# iospear600 register map
Registers are 32-bit, access not given, no defined reset value unless marked. A register's access mark holds for its fields unless they carry their own. Addresses are absolute; registers are grouped by the start of their names; [hi:lo] are bit positions; {n}, {i} and the like mark numbered series; 'fields as' and 'values as' point back to an identical list.

## TIMERB
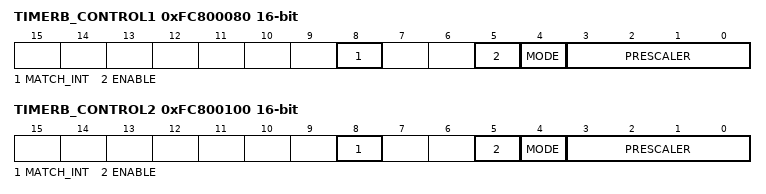
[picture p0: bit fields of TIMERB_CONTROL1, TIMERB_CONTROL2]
0xFC800080 TIMERB_CONTROL1 16-bit
  [8] MATCH_INT, [5] ENABLE, [4] MODE, [3:0] PRESCALER
0xFC800084 TIMERB_STATUS_INT_ACK1 16-bit
  [0] MATCH
0xFC800088 TIMERB_COMPARE1 16-bit
0xFC80008C TIMERB_COUNT1 16-bit
0xFC800090 TIMERB_REDG_CAPT1 16-bit
0xFC800094 TIMERB_FEDG_CAPT1 16-bit
0xFC800100 TIMERB_CONTROL2 16-bit
  [8] MATCH_INT, [5] ENABLE, [4] MODE, [3:0] PRESCALER
0xFC800104 TIMERB_STATUS_INT_ACK2 16-bit
  [0] MATCH
0xFC800108 TIMERB_COMPARE2 16-bit
0xFC80010C TIMERB_COUNT2 16-bit
0xFC800110 TIMERB_REDG_CAPT2 16-bit
0xFC800114 TIMERB_FEDG_CAPT2 16-bit

## TIMER1
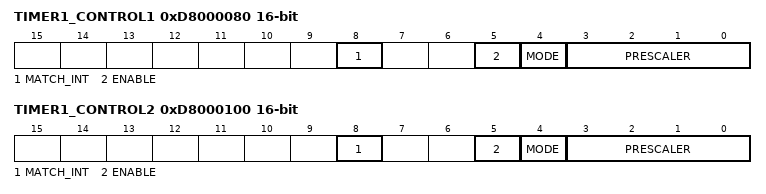
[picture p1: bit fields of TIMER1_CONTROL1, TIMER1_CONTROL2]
0xD8000080 TIMER1_CONTROL1 16-bit
  [8] MATCH_INT, [5] ENABLE, [4] MODE, [3:0] PRESCALER
0xD8000084 TIMER1_STATUS_INT_ACK1 16-bit
  [0] MATCH
0xD8000088 TIMER1_COMPARE1 16-bit
0xD800008C TIMER1_COUNT1 16-bit
0xD8000090 TIMER1_REDG_CAPT1 16-bit
0xD8000094 TIMER1_FEDG_CAPT1 16-bit
0xD8000100 TIMER1_CONTROL2 16-bit
  [8] MATCH_INT, [5] ENABLE, [4] MODE, [3:0] PRESCALER
0xD8000104 TIMER1_STATUS_INT_ACK2 16-bit
  [0] MATCH
0xD8000108 TIMER1_COMPARE2 16-bit
0xD800010C TIMER1_COUNT2 16-bit
0xD8000110 TIMER1_REDG_CAPT2 16-bit
0xD8000114 TIMER1_FEDG_CAPT2 16-bit

## TIMER2
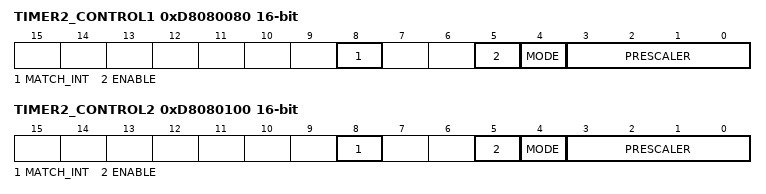
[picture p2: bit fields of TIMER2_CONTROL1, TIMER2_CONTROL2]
0xD8080080 TIMER2_CONTROL1 16-bit
  [8] MATCH_INT, [5] ENABLE, [4] MODE, [3:0] PRESCALER
0xD8080084 TIMER2_STATUS_INT_ACK1 16-bit
  [0] MATCH
0xD8080088 TIMER2_COMPARE1 16-bit
0xD808008C TIMER2_COUNT1 16-bit
0xD8080090 TIMER2_REDG_CAPT1 16-bit
0xD8080094 TIMER2_FEDG_CAPT1 16-bit
0xD8080100 TIMER2_CONTROL2 16-bit
  [8] MATCH_INT, [5] ENABLE, [4] MODE, [3:0] PRESCALER
0xD8080104 TIMER2_STATUS_INT_ACK2 16-bit
  [0] MATCH
0xD8080108 TIMER2_COMPARE2 16-bit
0xD808010C TIMER2_COUNT2 16-bit
0xD8080110 TIMER2_REDG_CAPT2 16-bit
0xD8080114 TIMER2_FEDG_CAPT2 16-bit

## SMI
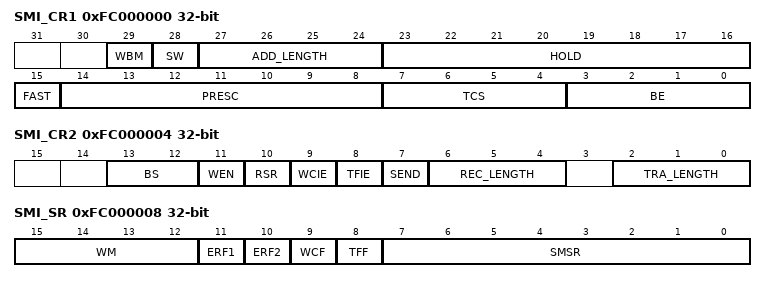
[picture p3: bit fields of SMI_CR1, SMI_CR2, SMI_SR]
0xFC000000 SMI_CR1
  [29] WBM, [28] SW, [27:24] ADD_LENGTH, [23:16] HOLD, [15] FAST, [14:8] PRESC, [7:4] TCS, [3:0] BE
0xFC000004 SMI_CR2
  [13:12] BS, [11] WEN, [10] RSR, [9] WCIE, [8] TFIE, [7] SEND, [6:4] REC_LENGTH, [2:0] TRA_LENGTH
0xFC000008 SMI_SR
  [15:12] WM, [11] ERF1, [10] ERF2, [9] WCF, [8] TFF, [7:0] SMSR
0xFC00000C SMI_TR
0xFC000010 SMI_RR

## GenMemCtrl
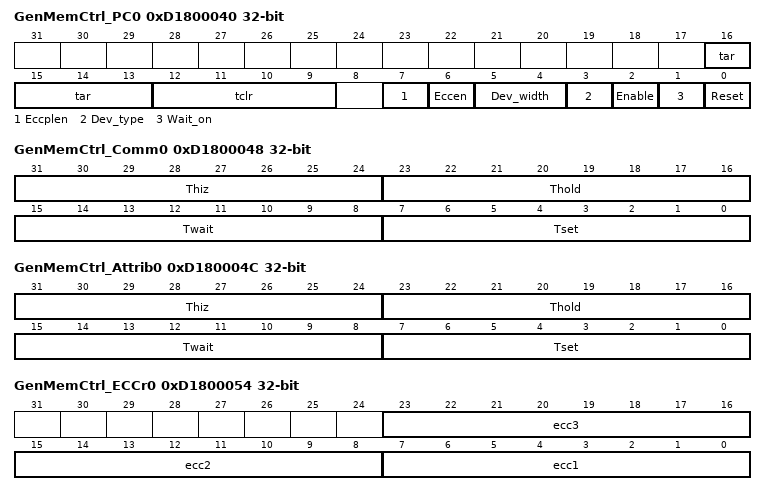
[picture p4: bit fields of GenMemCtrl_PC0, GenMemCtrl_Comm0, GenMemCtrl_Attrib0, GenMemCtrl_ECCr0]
0xD1800040 GenMemCtrl_PC0
  [16:13] tar, [12:9] tclr, [7] Eccplen, [6] Eccen, [5:4] Dev_width, [3] Dev_type, [2] Enable, [1] Wait_on, [0] Reset
0xD1800048 GenMemCtrl_Comm0
  [31:24] Thiz, [23:16] Thold, [15:8] Twait, [7:0] Tset
0xD180004C GenMemCtrl_Attrib0
  [31:24] Thiz, [23:16] Thold, [15:8] Twait, [7:0] Tset
0xD1800054 GenMemCtrl_ECCr0
  [23:16] ecc3, [15:8] ecc2, [7:0] ecc1
{0xD1800FE0+4i} GenMemCtrl_PeriphID{i} (i=0..3)
{0xD1800FF0+4i} GenMemCtrl_PCellID{i} (i=0..3)

## IrDA
0xD1000010 IrDA_CON
  [0] RUN
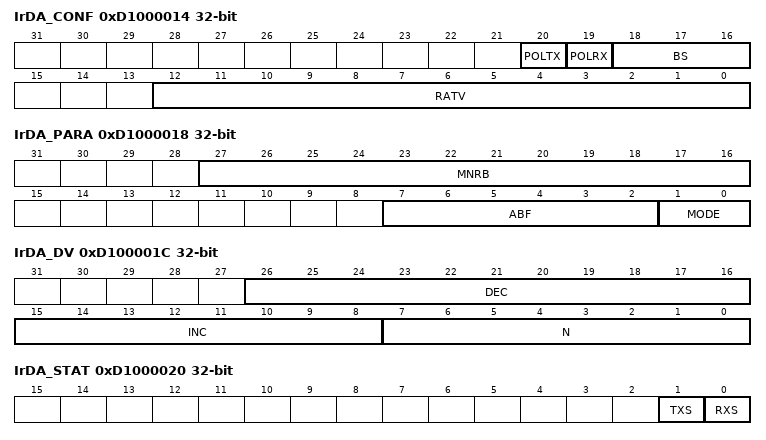
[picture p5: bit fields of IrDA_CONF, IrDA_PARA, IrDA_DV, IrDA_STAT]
0xD1000014 IrDA_CONF
  [20] POLTX, [19] POLRX, [18:16] BS, [12:0] RATV
0xD1000018 IrDA_PARA
  [27:16] MNRB, [7:2] ABF, [1:0] MODE
0xD100001C IrDA_DV
  [26:16] DEC, [15:8] INC, [7:0] N
0xD1000020 IrDA_STAT
  [1] TXS, [0] RXS
0xD1000024 IrDA_TFS
  [11:0] TFS
0xD1000028 IrDA_RFS
  [11:0] RFS
0xD100002C IrDA_TXB
0xD1000030 IrDA_RXB
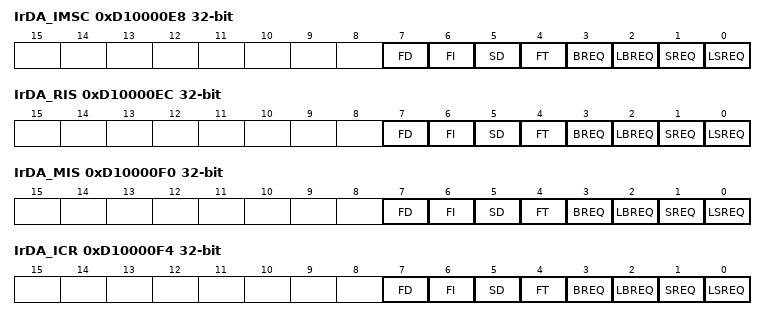
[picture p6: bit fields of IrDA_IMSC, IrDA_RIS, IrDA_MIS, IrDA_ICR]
0xD10000E8 IrDA_IMSC
  [7] FD, [6] FI, [5] SD, [4] FT, [3] BREQ, [2] LBREQ, [1] SREQ, [0] LSREQ
0xD10000EC IrDA_RIS
  fields as IrDA_IMSC
0xD10000F0 IrDA_MIS
  fields as IrDA_IMSC
0xD10000F4 IrDA_ICR
  fields as IrDA_IMSC
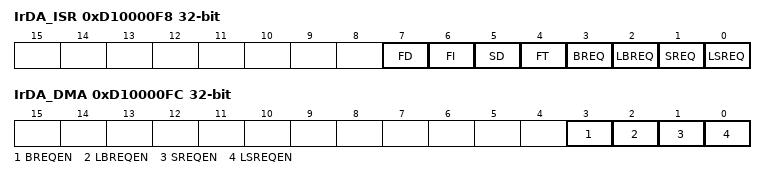
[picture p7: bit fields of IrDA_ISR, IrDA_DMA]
0xD10000F8 IrDA_ISR
  fields as IrDA_IMSC
0xD10000FC IrDA_DMA
  [3] BREQEN, [2] LBREQEN, [1] SREQEN, [0] LSREQEN

## IC
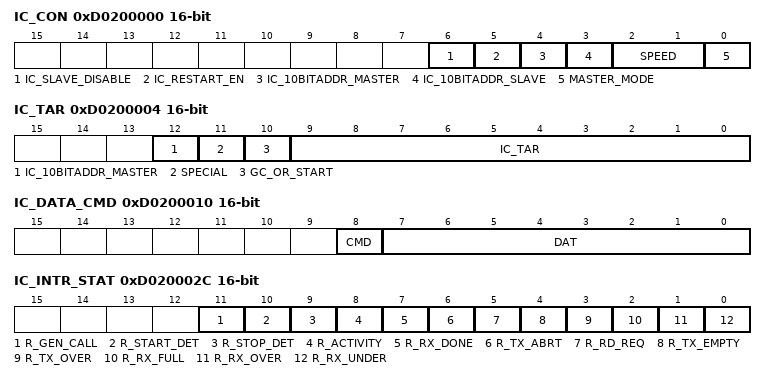
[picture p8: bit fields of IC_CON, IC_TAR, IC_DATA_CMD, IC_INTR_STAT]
0xD0200000 IC_CON 16-bit
  [6] IC_SLAVE_DISABLE, [5] IC_RESTART_EN, [4] IC_10BITADDR_MASTER, [3] IC_10BITADDR_SLAVE, [2:1] SPEED, [0] MASTER_MODE
0xD0200004 IC_TAR 16-bit
  [12] IC_10BITADDR_MASTER, [11] SPECIAL, [10] GC_OR_START, [9:0] IC_TAR
0xD0200008 IC_SAR 16-bit
  [9:0] IC_SAR
0xD020000C IC_HS_MADDR 16-bit
  [2:0] IC_HS_MAR
0xD0200010 IC_DATA_CMD 16-bit
  [8] CMD, [7:0] DAT
0xD0200014 IC_SS_SCL_HCNT 16-bit
0xD0200018 IC_SS_SCL_LCNT 16-bit
0xD020001C IC_FS_SCL_HCNT 16-bit
0xD0200020 IC_FS_SCL_LCNT 16-bit
0xD0200024 IC_HS_SCL_HCNT 16-bit
0xD0200028 IC_HS_SCL_LCNT 16-bit
0xD020002C IC_INTR_STAT 16-bit
  [11] R_GEN_CALL, [10] R_START_DET, [9] R_STOP_DET, [8] R_ACTIVITY, [7] R_RX_DONE, [6] R_TX_ABRT, [5] R_RD_REQ, [4] R_TX_EMPTY, [3] R_TX_OVER, [2] R_RX_FULL, [1] R_RX_OVER, [0] R_RX_UNDER
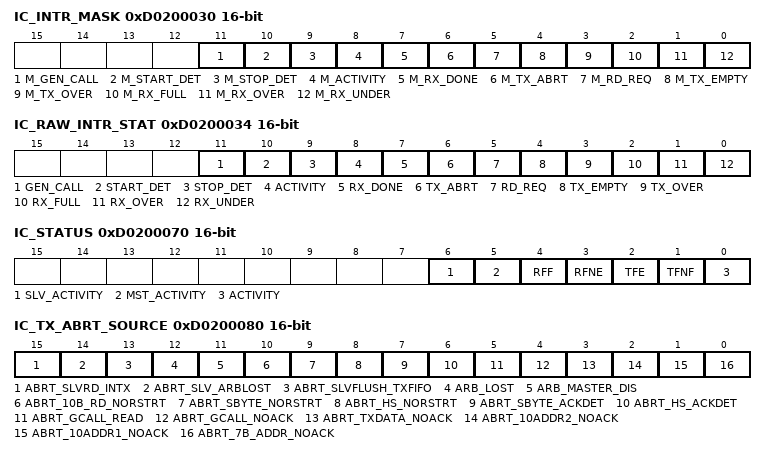
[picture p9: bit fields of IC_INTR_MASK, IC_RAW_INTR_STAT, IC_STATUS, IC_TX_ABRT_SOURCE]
0xD0200030 IC_INTR_MASK 16-bit
  [11] M_GEN_CALL, [10] M_START_DET, [9] M_STOP_DET, [8] M_ACTIVITY, [7] M_RX_DONE, [6] M_TX_ABRT, [5] M_RD_REQ, [4] M_TX_EMPTY, [3] M_TX_OVER, [2] M_RX_FULL, [1] M_RX_OVER, [0] M_RX_UNDER
0xD0200034 IC_RAW_INTR_STAT 16-bit
  [11] GEN_CALL, [10] START_DET, [9] STOP_DET, [8] ACTIVITY, [7] RX_DONE, [6] TX_ABRT, [5] RD_REQ, [4] TX_EMPTY, [3] TX_OVER, [2] RX_FULL, [1] RX_OVER, [0] RX_UNDER
0xD0200038 IC_RX_TL 16-bit
  [7:0] RX_TL
0xD020003C IC_TX_TL 16-bit
  [7:0] TX_TL
0xD0200040 IC_CLR_INTR 16-bit
  [0] CLR_INTR
0xD0200044 IC_CLR_RX_UNDER 16-bit
0xD0200048 IC_CLR_RX_OVER 16-bit
0xD020004C IC_CLR_TX_OVER 16-bit
0xD0200050 IC_CLR_RD_REQ 16-bit
0xD0200054 IC_CLR_TX_ABRT 16-bit
0xD0200058 IC_CLR_RX_DONE 16-bit
0xD020005C IC_CLR_ACTIVITY 16-bit
0xD0200060 IC_CLR_STOP_DET 16-bit
0xD0200064 IC_CLR_START_DET 16-bit
0xD0200068 IC_CLR_GEN_CALL 16-bit
0xD020006C IC_ENABLE 16-bit
  [0] ENABLE
0xD0200070 IC_STATUS 16-bit
  [6] SLV_ACTIVITY, [5] MST_ACTIVITY, [4] RFF, [3] RFNE, [2] TFE, [1] TFNF, [0] ACTIVITY
0xD0200074 IC_TXFLR 16-bit
  [3:0] TXFLR
0xD0200078 IC_RXFLR 16-bit
  [3:0] RXFLR
0xD0200080 IC_TX_ABRT_SOURCE 16-bit
  [15] ABRT_SLVRD_INTX, [14] ABRT_SLV_ARBLOST, [13] ABRT_SLVFLUSH_TXFIFO, [12] ARB_LOST, [11] ARB_MASTER_DIS, [10] ABRT_10B_RD_NORSTRT, [9] ABRT_SBYTE_NORSTRT, [8] ABRT_HS_NORSTRT, [7] ABRT_SBYTE_ACKDET, [6] ABRT_HS_ACKDET, [5] ABRT_GCALL_READ, [4] ABRT_GCALL_NOACK, [3] ABRT_TXDATA_NOACK, [2] ABRT_10ADDR2_NOACK, [1] ABRT_10ADDR1_NOACK, [0] ABRT_7B_ADDR_NOACK
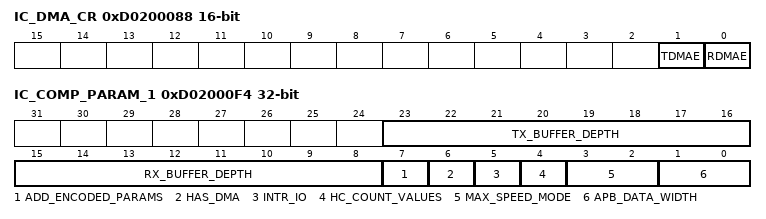
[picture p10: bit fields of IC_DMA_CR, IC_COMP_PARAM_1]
0xD0200088 IC_DMA_CR 16-bit
  [1] TDMAE, [0] RDMAE
0xD020008C IC_DMA_TDLR 16-bit
  [2:0] DMATDL
0xD0200090 IC_DMA_RDLR 16-bit
  [2:0] DMARDL
0xD02000F4 IC_COMP_PARAM_1
  [23:16] TX_BUFFER_DEPTH, [15:8] RX_BUFFER_DEPTH, [7] ADD_ENCODED_PARAMS, [6] HAS_DMA, [5] INTR_IO, [4] HC_COUNT_VALUES, [3:2] MAX_SPEED_MODE, [1:0] APB_DATA_WIDTH
0xD02000F8 IC_COMP_VERSION
0xD02000FC IC_COMP_TYPE

## ADC
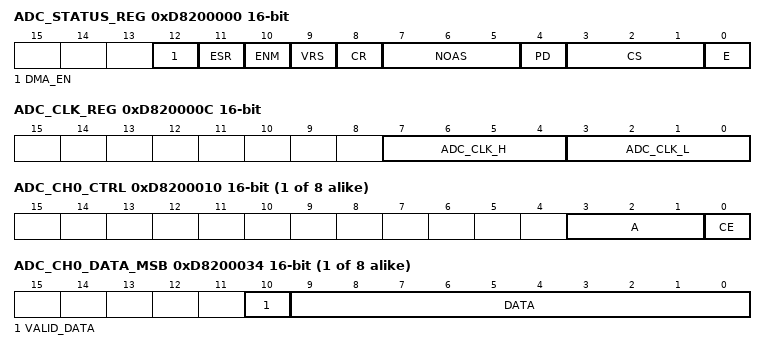
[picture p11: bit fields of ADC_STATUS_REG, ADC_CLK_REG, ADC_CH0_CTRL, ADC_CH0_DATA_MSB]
0xD8200000 ADC_STATUS_REG 16-bit
  [12] DMA_EN, [11] ESR, [10] ENM, [9] VRS, [8] CR, [7:5] NOAS, [4] PD, [3:1] CS, [0] E
0xD820000C ADC_CLK_REG 16-bit
  [7:4] ADC_CLK_H, [3:0] ADC_CLK_L
{0xD8200010+4i} ADC_CH{i}_CTRL 16-bit (i=0..7)
  [3:1] A, [0] CE
{0xD8200030+8i} ADC_CH{i}_DATA_LSB 16-bit (i=0..7)
  [6:0] DATA
{0xD8200034+8i} ADC_CH{i}_DATA_MSB 16-bit (i=0..7)
  [10] VALID_DATA, [9:0] DATA
0xD8200070 ADC_SCAN_RATE_LO 16-bit
0xD8200074 ADC_SCAN_RATE_HI 16-bit
0xD8200078 ADC_AVERAGE_REG_LSB 16-bit
  [6:0] DATA
0xD820007C ADC_AVERAGE_REG_MSB 16-bit
  [9:0] DATA

## I2S
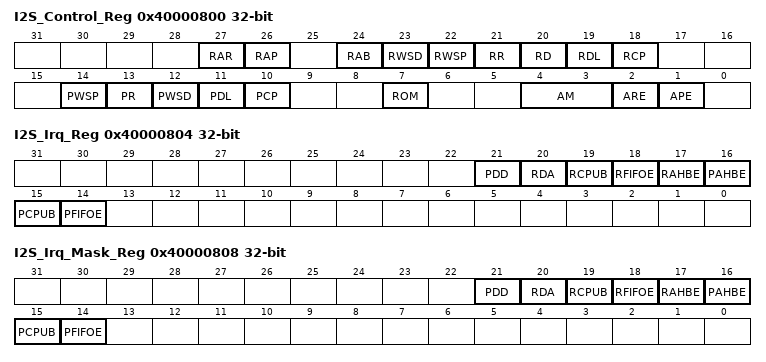
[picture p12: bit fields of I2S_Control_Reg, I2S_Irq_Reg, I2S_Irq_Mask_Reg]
0x40000800 I2S_Control_Reg
  [27] RAR, [26] RAP, [24] RAB, [23] RWSD, [22] RWSP, [21] RR, [20] RD, [19] RDL, [18] RCP, [14] PWSP, [13] PR, [12] PWSD, [11] PDL, [10] PCP, [7] ROM, [4:3] AM, [2] ARE, [1] APE
0x40000804 I2S_Irq_Reg
  [21] PDD, [20] RDA, [19] RCPUB, [18] RFIFOE, [17] RAHBE, [16] PAHBE, [15] PCPUB, [14] PFIFOE
0x40000808 I2S_Irq_Mask_Reg
  fields as I2S_Irq_Reg
0x4000080C I2S_Status_Reg
  [26] RFIFOE
0x40000818 I2S_Play_Desc_Reg
0x4000081C I2S_Rec_Desc_Reg
0x40000820 I2S_Rec_Data_Cnt_Reg

## MLEXP
{0xCFFFDFFC+4i} MLEXP_PL{i} (i=1..3)
  [3:0] pry_lvl
0xCFFFE090 MLEXP_COMP_VERSION

## MLEPX
0xCFFFE03C MLEPX_EBTCOUNT
  [9:0] ebt_cntr
0xCFFFE040 MLEPX_EBT_EN
  [0] ebt_enab
0xCFFFE044 MLEPX_EBT
  [0] early_brst_term
0xCFFFE048 MLEPX_DFT_MST
  [3:0] def_mst

## XLAT
{0xCFFFE400+4i} XLAT_ENT{i} (i=0..5)
  [14:0] add_segment

## SE2H
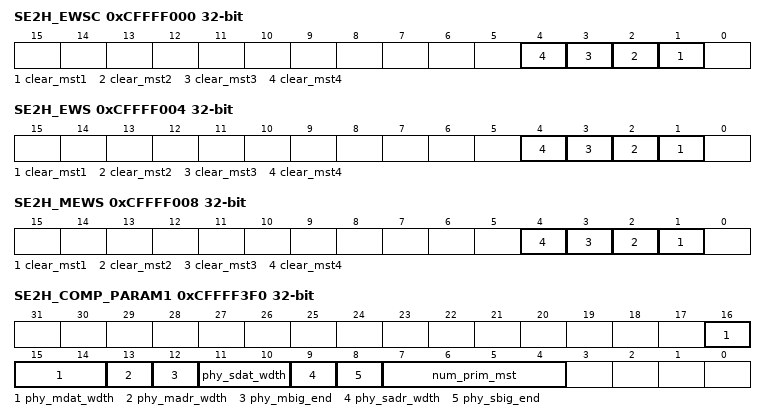
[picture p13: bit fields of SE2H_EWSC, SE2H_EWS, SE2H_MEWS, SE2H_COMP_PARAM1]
0xCFFFF000 SE2H_EWSC
  [n] clear_mst{n} (n=1..4)
0xCFFFF004 SE2H_EWS
  [n] clear_mst{n} (n=1..4)
0xCFFFF008 SE2H_MEWS
  [n] clear_mst{n} (n=1..4)
0xCFFFF3F0 SE2H_COMP_PARAM1
  [16:14] phy_mdat_wdth, [13] phy_madr_wdth, [12] phy_mbig_end, [11:10] phy_sdat_wdth, [9] phy_sadr_wdth, [8] phy_sbig_end, [7:4] num_prim_mst
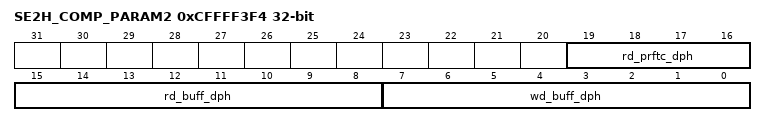
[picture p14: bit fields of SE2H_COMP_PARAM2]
0xCFFFF3F4 SE2H_COMP_PARAM2
  [19:16] rd_prftc_dph, [15:8] rd_buff_dph, [7:0] wd_buff_dph
0xCFFFF3F8 SE2H_COMP_VERSION
0xCFFFF3FC SE2H_COMP_TYPE

## ME2H
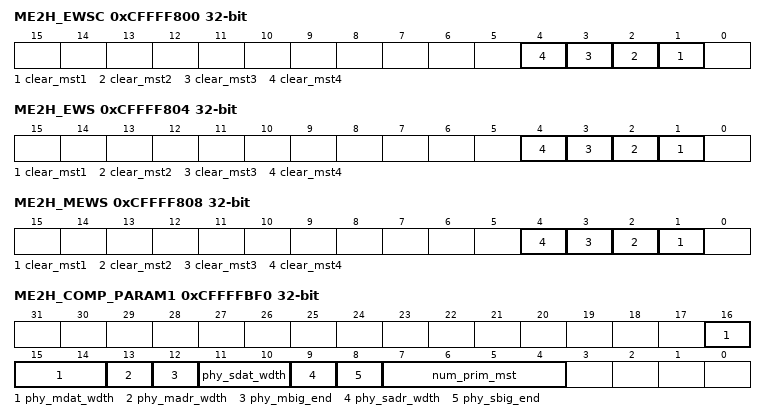
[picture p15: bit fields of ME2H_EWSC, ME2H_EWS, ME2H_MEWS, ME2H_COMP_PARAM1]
0xCFFFF800 ME2H_EWSC
  [n] clear_mst{n} (n=1..4)
0xCFFFF804 ME2H_EWS
  [n] clear_mst{n} (n=1..4)
0xCFFFF808 ME2H_MEWS
  [n] clear_mst{n} (n=1..4)
0xCFFFFBF0 ME2H_COMP_PARAM1
  [16:14] phy_mdat_wdth, [13] phy_madr_wdth, [12] phy_mbig_end, [11:10] phy_sdat_wdth, [9] phy_sadr_wdth, [8] phy_sbig_end, [7:4] num_prim_mst
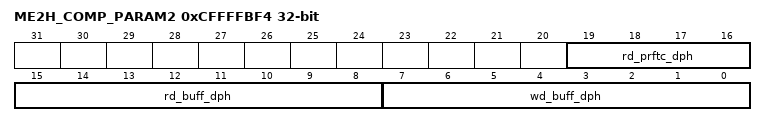
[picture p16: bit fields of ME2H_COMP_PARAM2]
0xCFFFFBF4 ME2H_COMP_PARAM2
  [19:16] rd_prftc_dph, [15:8] rd_buff_dph, [7:0] wd_buff_dph
0xCFFFFBF8 ME2H_COMP_VERSION
0xCFFFFBFC ME2H_COMP_TYPE
